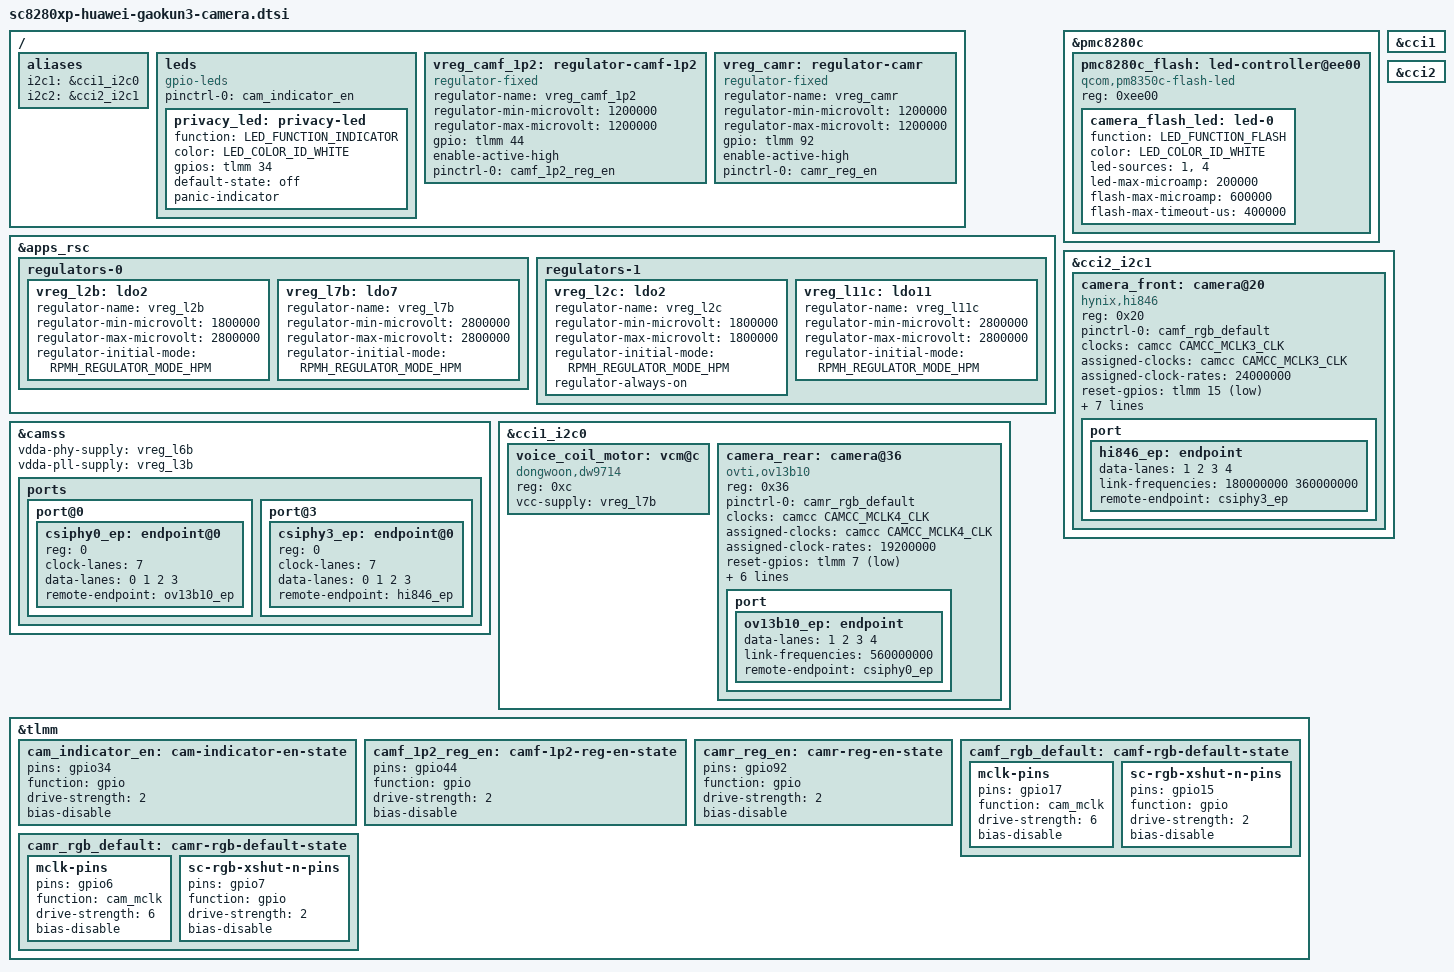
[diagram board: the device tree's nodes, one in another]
// SPDX-License-Identifier: BSD-3-Clause
/*
 * Copyright (c) 2021, The Linux Foundation. All rights reserved.
 */

#include <dt-bindings/leds/common.h>

/* remove due to gpio pins collision, skip 2nd instance won't break things */
/delete-node/ &cci1_i2c1;
/delete-node/ &cci1_i2c1_default;
/delete-node/ &cci1_i2c1_sleep;

/* override */
/delete-node/ &vreg_l2b;

/ {
	aliases {
		i2c1 = &cci1_i2c0;
		i2c2 = &cci2_i2c1;
	};

	leds {
		compatible = "gpio-leds";

		pinctrl-0 = <&cam_indicator_en>;
		pinctrl-names = "default";

		privacy_led: privacy-led {
			function = LED_FUNCTION_INDICATOR;
			color = <LED_COLOR_ID_WHITE>;
			gpios = <&tlmm 34 GPIO_ACTIVE_HIGH>;
			default-state = "off";
			panic-indicator;
		};

		/*
		 * GPIO93 曾在这里被当成 flash LED（white:flash）——实测打脉冲不亮（#106），
		 * 连带的 camera_flash_en pinctrl 状态一起删了。真闪光灯是下面 &pmc8280c 的 led-0。
		 */
	};

	vreg_camf_1p2: regulator-camf-1p2 {
		compatible = "regulator-fixed";

		regulator-name = "vreg_camf_1p2";
		regulator-min-microvolt = <1200000>;
		regulator-max-microvolt = <1200000>;

		gpio = <&tlmm 44 GPIO_ACTIVE_HIGH>;
		enable-active-high;

		pinctrl-0 = <&camf_1p2_reg_en>;
		pinctrl-names = "default";
	};

	vreg_camr: regulator-camr {
		compatible = "regulator-fixed";

		regulator-name = "vreg_camr";
		/* Rear sensor digital core rail, gated by GPIO92 (Windows CAMS_RES_QRD).
		 * The board LDO sets the real voltage; 1.2V is OV13B10 DVDD nominal. */
		regulator-min-microvolt = <1200000>;
		regulator-max-microvolt = <1200000>;

		gpio = <&tlmm 92 GPIO_ACTIVE_HIGH>;
		enable-active-high;

		pinctrl-0 = <&camr_reg_en>;
		pinctrl-names = "default";
	};
};

&apps_rsc {
	regulators-0 {
		vreg_l2b: ldo2 {
			regulator-name = "vreg_l2b";
			regulator-min-microvolt = <1800000>;
			regulator-max-microvolt = <2800000>;
			regulator-initial-mode = <RPMH_REGULATOR_MODE_HPM>;
		};

		vreg_l7b: ldo7 {
			regulator-name = "vreg_l7b";
			regulator-min-microvolt = <2800000>;
			regulator-max-microvolt = <2800000>;
			regulator-initial-mode = <RPMH_REGULATOR_MODE_HPM>;
		};
	};

	regulators-1 {
		vreg_l2c: ldo2 {
			regulator-name = "vreg_l2c";
			regulator-min-microvolt = <1800000>;
			regulator-max-microvolt = <1800000>;
			regulator-initial-mode = <RPMH_REGULATOR_MODE_HPM>;
			/* may be used in audio codec driver (ACD) too */
			// regulator-allow-set-load;
			// regulator-allowed-modes = <RPMH_REGULATOR_MODE_LPM
			// 			   RPMH_REGULATOR_MODE_HPM>;
			regulator-always-on;
		};

		vreg_l11c: ldo11 {
			regulator-name = "vreg_l11c";
			regulator-min-microvolt = <2800000>;
			regulator-max-microvolt = <2800000>;
			regulator-initial-mode = <RPMH_REGULATOR_MODE_HPM>;
		};
	};
};

/*
 * 闪光灯（patches/0036）：Windows 的 \_SB.FLSH 设备没有 GPIO/I2C 资源 ⇒ 走 PMIC 闪光模块
 * （pmc8280c = PM8350C，主线 leds-qcom-flash）；GPIO93 直驱实测不亮（#106）。
 * 2026-09-14 内核 #19 四路逐个 torch 实测（用户看背面）：LED 接在 **1 + 4 路**（#110）。
 * ⚠️ 电流上限是【保守假设】不是模组手册值：torch 合计 200 mA、flash 600 mA / 400 ms。
 * ⚠️ 故意不在 ov13b10 节点上写 flash-leds：那会让 v4l2-async 再多等一个 subdev。
 */
&pmc8280c {
	pmc8280c_flash: led-controller@ee00 {
		compatible = "qcom,pm8350c-flash-led", "qcom,spmi-flash-led";
		reg = <0xee00>;

		camera_flash_led: led-0 {
			function = LED_FUNCTION_FLASH;
			color = <LED_COLOR_ID_WHITE>;
			led-sources = <1>, <4>;
			led-max-microamp = <200000>;
			flash-max-microamp = <600000>;
			flash-max-timeout-us = <400000>;
		};
	};
};

&camss {
	/*
	 * CSIPHY0, CSIPHY1 1.2v = l4d, 0.88v = l6d
	 * CSIPHY2, CSIPHY3 1.2v = l3b, 0.88v = l6b
	 *
	 * drivers/media/platform/qcom/camss/camss.c
	 */

	vdda-phy-supply = <&vreg_l6b>;
	vdda-pll-supply = <&vreg_l3b>;

	status = "okay";

	ports {
		/*
		 * port@0: csiphy0 -> rear OV13B10. Restored 2026-09-14 with the
		 * board's real power sequence (Windows CAMS_RES_QRD.bin, see
		 * docs/stage4-findings.md #106): LDO2_B 2.8V (vdda), LDO2_C 1.8V
		 * (vddio), GPIO92-gated rail (vddd), reset GPIO7, MCLK4 24MHz.
		 * L2B is shared with the panel's vddi (1.8V vote); the sensor
		 * driver raises it to 2.8V while powered, exactly like Windows.
		 */
		port@0 {
			csiphy0_ep: endpoint@0 {
				reg = <0>;

				clock-lanes = <7>;
				data-lanes = <0 1 2 3>;
				remote-endpoint = <&ov13b10_ep>;
			};
		};

		port@3 {
			csiphy3_ep: endpoint@0 {
				reg = <0>;

				clock-lanes = <7>;
				data-lanes = <0 1 2 3>;
				remote-endpoint = <&hi846_ep>;
			};
		};
	};
};

&cci1 {
	status = "okay";
};

&cci1_i2c0 {
	voice_coil_motor: vcm@c {
		compatible = "dongwoon,dw9714";
		reg = <0xc>;
		vcc-supply = <&vreg_l7b>; /* FIXME: require l2c on first */
	};

	/*
	 * https://source.puri.sm/Librem5/linux/-/blob/pureos/latest/drivers/media/i2c/s5k3l6xx.c
	 *
	 * poor image quality, no plan to extract downstream registers
	 * configuration for it. I think nobody uses camera without tuning
	 * to take photos. Front camera with conference is enough.
	 *
	 * This sensor has never been detected on 2023 model
	 */
	/*
	 * Rear camera. The board's Windows driver package ships two rear modules
	 * (ofilm_ov13b10 and lijing_s5k3l6); on this unit a bus scan with the
	 * rails up (2026-09-14, docs/stage4-findings.md #106) answered at 0x36
	 * (OV13B10) and 0x50 (module EEPROM), nothing at 0x10 - so it is the
	 * OV13B10. Rails from CAMS_RES_QRD.bin: LDO2_B 2.8V (avdd, shared with
	 * the panel's 1.8V vddi - the driver raises it while powered), LDO2_C
	 * 1.8V (dovdd), GPIO92-gated core rail (dvdd), reset GPIO7, MCLK4.
	 * The upstream ov13b10 register tables assume a 19.2 MHz MCLK.
	 */
	camera_rear: camera@36 {
		compatible = "ovti,ov13b10";
		reg = <0x36>;

		pinctrl-0 = <&camr_rgb_default>;
		pinctrl-names = "default";

		clocks = <&camcc CAMCC_MCLK4_CLK>;
		assigned-clocks = <&camcc CAMCC_MCLK4_CLK>;
		assigned-clock-rates = <19200000>;

		reset-gpios = <&tlmm 7 GPIO_ACTIVE_LOW>;

		avdd-supply = <&vreg_l2b>;
		dovdd-supply = <&vreg_l2c>;
		dvdd-supply = <&vreg_camr>;

		lens-focus = <&voice_coil_motor>;

		orientation = <1>;
		rotation = <180>; /* FIXME */

		port {
			ov13b10_ep: endpoint {
				data-lanes = <1 2 3 4>;
				link-frequencies = /bits/ 64 <560000000>;
				remote-endpoint = <&csiphy0_ep>;
			};
		};
	};

	// eeprom@50/51 <= l2c
};

&cci2 {
	status = "okay";
};

&cci2_i2c1 {
	// ??? @10 appears when CAMCC_MCLK3_CLK@19.2MHz
	// On 2023 model, S5K4H7@2d, image quality is better than hi846

	camera_front: camera@20 {
		compatible = "hynix,hi846";
		reg = <0x20>;

		pinctrl-0 = <&camf_rgb_default>;
		pinctrl-names = "default";

		clocks = <&camcc CAMCC_MCLK3_CLK>;

		assigned-clocks = <&camcc CAMCC_MCLK3_CLK>;
		assigned-clock-rates = <24000000>;

		reset-gpios = <&tlmm 15 GPIO_ACTIVE_LOW>;
		vddio-supply = <&vreg_l2c>;
		vdda-supply = <&vreg_l11c>;
		vddd-supply = <&vreg_camf_1p2>;

		leds = <&privacy_led>;
		led-names = "privacy";

		orientation = <0>;	/* Front facing */
		rotation = <0>;

		port {
			hi846_ep: endpoint {
				data-lanes = <1 2 3 4>;
				link-frequencies = /bits/ 64 <180000000 360000000>;
				remote-endpoint = <&csiphy3_ep>;
			};
		};
	};

	// eeprom@50
	// actuator???@58, 2023 only
};

&tlmm {
	cam_indicator_en: cam-indicator-en-state {
		pins = "gpio34";
		function = "gpio";
		drive-strength = <2>;
		bias-disable;
	};


	camf_1p2_reg_en: camf-1p2-reg-en-state {
		pins = "gpio44";
		function = "gpio";
		drive-strength = <2>;
		bias-disable;
	};

	camr_reg_en: camr-reg-en-state {
		pins = "gpio92";
		function = "gpio";
		drive-strength = <2>;
		bias-disable;
	};

	camf_rgb_default: camf-rgb-default-state {
		mclk-pins {
			pins = "gpio17";
			function = "cam_mclk";
			drive-strength = <6>;
			bias-disable;
		};

		sc-rgb-xshut-n-pins {
			pins = "gpio15";
			function = "gpio";
			drive-strength = <2>;
			bias-disable;
		};
	};

	camr_rgb_default: camr-rgb-default-state {
		mclk-pins {
			pins = "gpio6";
			function = "cam_mclk";
			drive-strength = <6>;
			bias-disable;
		};

		sc-rgb-xshut-n-pins {
			pins = "gpio7";
			function = "gpio";
			drive-strength = <2>;
			bias-disable;
		};
	};
};
